# nrf54lilium_network register map
Vendor: Nordic Semiconductor; Series: nrf54; File version: 1
CPU: CM33 r0p4, little endian, MPU, no FPU, 3 interrupt priority bits, 30 interrupts
Registers are 32-bit, read-write, reset 0x0 unless marked. A register's access mark holds for its fields unless they carry their own. Offsets are from the block's base; [hi:lo] are bit positions; lines under a group give offsets from that group; {n}, {i} and the like mark numbered series; 'fields as' and 'values as' point back to an identical list.

## CCM — AES CCM mode encryption
Base 0x4100E000; alternate view of AAR
0x00 TASKS_CONFIG wo — Fetches AES Key and CCM Nonce from CONFIGPTR job list into the KEY and NONCE registers.
  [0] TASKS_CONFIG
    1=Trigger task
0x04 TASKS_CRYPT wo — Start encryption/decryption. This operation will stop by itself when completed.
  [0] TASKS_CRYPT
    1=Trigger task
0x08 TASKS_STOP wo — Stop encryption/decryption
  [0] TASKS_STOP
    1=Trigger task
0x0C TASKS_RATEOVERRIDE wo — Override DATARATE setting in MODE register with the contents of the RATEOVERRIDE register for any ongoing encryption/decryption
  [0] TASKS_RATEOVERRIDE
    1=Trigger task
0x10 TASKS_PROCESS wo — Fetches and processes one byte from INPTR in manual data rate mode
  [0] TASKS_PROCESS
    1=Trigger task
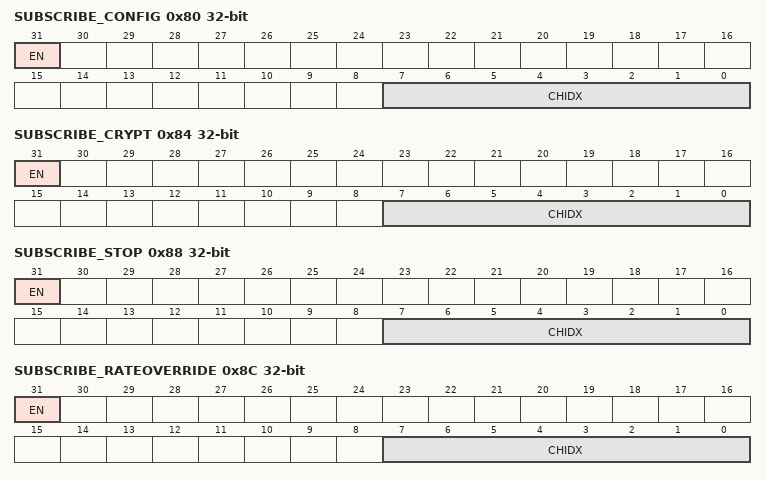
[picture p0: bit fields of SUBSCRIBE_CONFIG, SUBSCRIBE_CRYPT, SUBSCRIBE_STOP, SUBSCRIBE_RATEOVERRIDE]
0x80 SUBSCRIBE_CONFIG — Subscribe configuration for task CONFIG
  [31] EN
    0=Disabled (Disable subscription); 1=Enabled (Enable subscription)
  [7:0] CHIDX — DPPI channel that task CONFIG will subscribe to
0x84 SUBSCRIBE_CRYPT — Subscribe configuration for task CRYPT
  [31] EN
    values as SUBSCRIBE_CONFIG.EN
  [7:0] CHIDX — DPPI channel that task CRYPT will subscribe to
0x88 SUBSCRIBE_STOP — Subscribe configuration for task STOP
  [31] EN
    values as SUBSCRIBE_CONFIG.EN
  [7:0] CHIDX — DPPI channel that task STOP will subscribe to
0x8C SUBSCRIBE_RATEOVERRIDE — Subscribe configuration for task RATEOVERRIDE
  [31] EN
    values as SUBSCRIBE_CONFIG.EN
  [7:0] CHIDX — DPPI channel that task RATEOVERRIDE will subscribe to
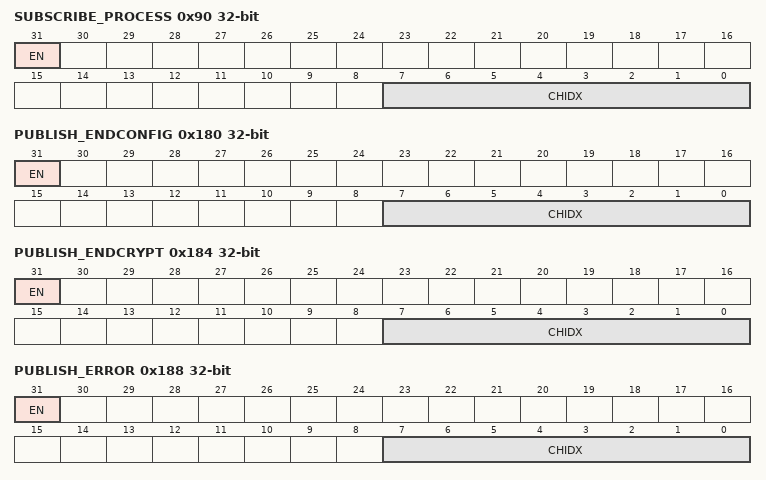
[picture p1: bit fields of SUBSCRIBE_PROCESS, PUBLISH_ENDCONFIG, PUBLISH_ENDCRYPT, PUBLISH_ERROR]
0x90 SUBSCRIBE_PROCESS — Subscribe configuration for task PROCESS
  [31] EN
    values as SUBSCRIBE_CONFIG.EN
  [7:0] CHIDX — DPPI channel that task PROCESS will subscribe to
0x100 EVENTS_ENDCONFIG — Configuration data has been loaded
  [0] EVENTS_ENDCONFIG
    0=NotGenerated (Event not generated); 1=Generated (Event generated)
0x104 EVENTS_ENDCRYPT — Encrypt/decrypt complete
  [0] EVENTS_ENDCRYPT
    values as EVENTS_ENDCONFIG.EVENTS_ENDCONFIG
0x108 EVENTS_ERROR — CCM error event
  [0] EVENTS_ERROR
    values as EVENTS_ENDCONFIG.EVENTS_ENDCONFIG
0x180 PUBLISH_ENDCONFIG — Publish configuration for event ENDCONFIG
  [31] EN
    0=Disabled (Disable publishing); 1=Enabled (Enable publishing)
  [7:0] CHIDX — DPPI channel that event ENDCONFIG will publish to.
0x184 PUBLISH_ENDCRYPT — Publish configuration for event ENDCRYPT
  [31] EN
    values as PUBLISH_ENDCONFIG.EN
  [7:0] CHIDX — DPPI channel that event ENDCRYPT will publish to.
0x188 PUBLISH_ERROR — Publish configuration for event ERROR
  [31] EN
    values as PUBLISH_ENDCONFIG.EN
  [7:0] CHIDX — DPPI channel that event ERROR will publish to.
0x200 SHORTS — Shortcuts between local events and tasks
  [0] ENDCONFIG_CRYPT — Shortcut between event ENDCONFIG and task CRYPT
    0=Disabled (Disable shortcut); 1=Enabled (Enable shortcut)
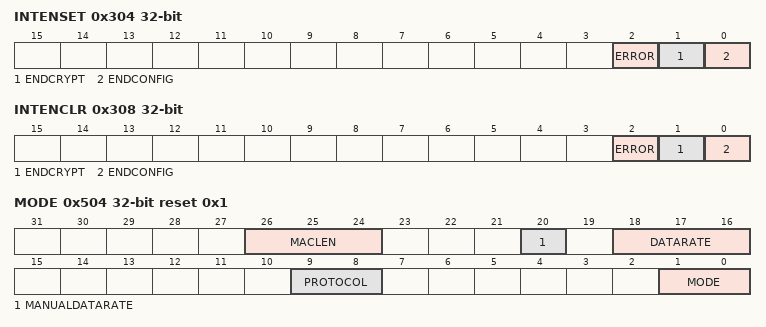
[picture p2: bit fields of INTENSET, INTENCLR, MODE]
0x304 INTENSET — Enable interrupt
  [all] fields
    on read: 0=Disabled (Read: Disabled); 1=Enabled (Read: Enabled) | on write: 1=Set (Enable)
  [2] ERROR — Write '1' to enable interrupt for event ERROR
  [1] ENDCRYPT — Write '1' to enable interrupt for event ENDCRYPT
  [0] ENDCONFIG — Write '1' to enable interrupt for event ENDCONFIG
0x308 INTENCLR — Disable interrupt
  [all] fields
    on read: 0=Disabled (Read: Disabled); 1=Enabled (Read: Enabled) | on write: 1=Clear (Disable)
  [2] ERROR — Write '1' to disable interrupt for event ERROR
  [1] ENDCRYPT — Write '1' to disable interrupt for event ENDCRYPT
  [0] ENDCONFIG — Write '1' to disable interrupt for event ENDCONFIG
0x400 MACSTATUS ro — MAC check result
  [0] MACSTATUS — The result of the MAC check performed during the previous decryption operation
    0=CheckFailed (MAC check failed); 1=CheckPassed (MAC check passed)
0x404 ERRORSTATUS ro
  [1:0] ERRORSTATUS — Error status when the ERROR event is generated
    0=No errors have occurred; 1=PrematureInptrEnd (End of INPTR job list before CCM data structure was read.); 2=PrematureOutptrEnd (End of OUTPTR job list before CCM data structure was read.); 3=EncryptionTooSlow (Encryption of the unencrypted CCM data structure did not complete in time.)
0x500 ENABLE
  [1:0] ENABLE — Enable or disable CCM
    0=Disabled; 2=Enabled
0x504 MODE reset 0x1 — Operation mode
  [26:24] MACLEN — CCM MAC length (bytes)
    0=M0 (M = 0 This is a special case for CCM* where encryption is required but not authentication); 1=M4; 2=M6; 3=M8; 4=M10; 5=M12; 6=M14; 7=M16
  [20] MANUALDATARATE — When enabled, the INPTR data structure will process one byte each time the PROCESS task is triggered. This can be used to support various data rates for on-the-fly encryption/decryption modes.
    0=Disable manual data rate; 1=Enable manual data rate
  [18:16] DATARATE — Radio data rate that the CCM shall run synchronous with
    0=125Kbit (125 Kbps); 1=250Kbit (250 Kbps); 2=500Kbps; 3=1Mbps; 4=2Mbit (2 Mbps); 5=4Mbit (4 Mbps)
  [9:8] PROTOCOL — Protocols that uses Crypto IP Due to the differences in BLE and 802.15.4 packets, HW needs to have a separation between them.
    0=CCM_BLE (BLE packet format); 1=CCM_154 (802.15.4 packet format)
  [1:0] MODE — The mode of operation to be used. The settings in this register apply when the CRYPT task is triggered.
    0=Encryption (AES CCM packet encryption mode); 1=Decryption (AES CCM packet decryption mode); 2=FastDecryption (AES fast decrypt mode. This mode will run CCM decryption as fast as possible, i.e. not locked to a radio data rate. This can be used when a packet has been completely received.)
0x510 KEY group — Unspecified
  {0x0+4j} VALUE[{j}] (j=0..3) — Description collection: 128-bit AES key
    [31:0] VALUE — AES 128-bit key value, bits (32*(i+1))-1 : (32*i)
0x520 NONCE group — Unspecified
  {0x0+4j} VALUE[{j}] (j=0..3) — Description collection: 13-byte NONCE vector Only the lower 13 bytes are used
    [31:0] VALUE — NONCE value, bits (32*(i+1))-1 : (32*i)
0x530 INPTR — Input pointer Points to a job list containing unencrypted CCM data structure in Encryption mode Points to a job list containing encrypted CCM data structure in Decryption mode
  [31:0] INPTR — Input pointer
0x534 INAMOUNT ro — Number of bytes read from the input data, not including the job list structure
  [31:0] INAMOUNT — Number of bytes read from the input data
0x538 OUTPTR — Output pointer Points to a job list containing encrypted CCM data structure in Encryption mode Points to a job list containing decrypted CCM data structure in Decryption mode
  [31:0] OUTPTR — Output pointer
0x53C OUTAMOUNT ro — Number of bytes available in the output data, not including the job list structure
  [31:0] OUTAMOUNT — Number of bytes available in the output data
0x540 RATEOVERRIDE — Data rate override setting.
  [2:0] RATEOVERRIDE
    0=1Mbit (1 Mbps); 1=2Mbit (2 Mbps); 2=125Kbps; 3=500Kbps; 4=4Mbit (4 Mbps)
0x544 ADATAMASK reset 0xE3 — CCM adata mask.
  [7:0] ADATAMASK — CCM adata mask. The rationale for this is to support on-the-fly masking of BLE header, as per the Bluetooth Spec.
